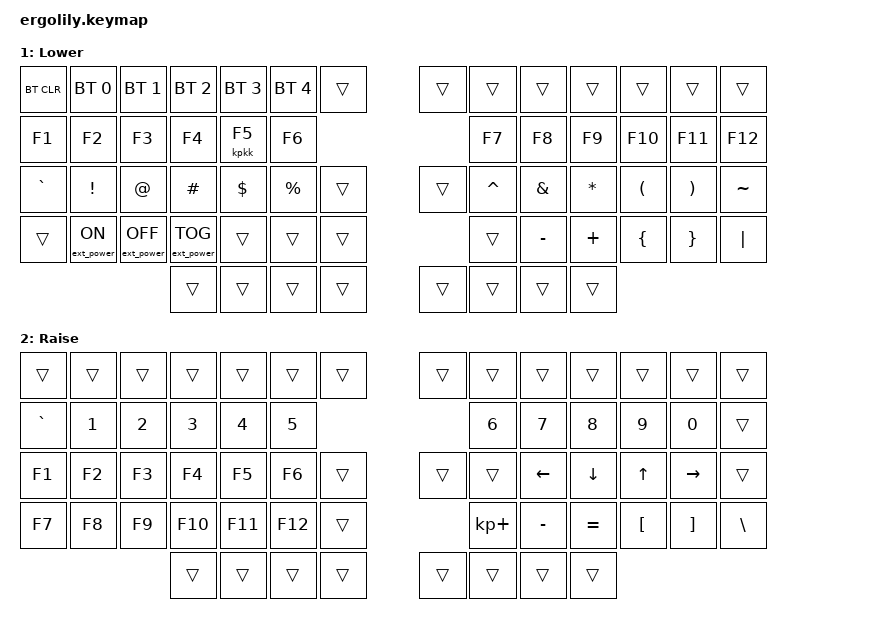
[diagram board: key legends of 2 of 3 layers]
/*
 * Copyright (c) 2020 The ZMK Contributors
 *
 * SPDX-License-Identifier: MIT
 */

 //This file is the board default. It is overridden if there's anything in config/ergolily.conf. I encourage you to edit that instead of this file for a custom keymap, and leave this as the fallback.

#include <behaviors.dtsi>
#include <dt-bindings/zmk/keys.h>
#include <dt-bindings/zmk/bt.h>
#include <dt-bindings/zmk/ext_power.h>

/ {
    keymap {
        compatible = "zmk,keymap";

        default_layer {
            display-name = "Default";
            bindings = <
&kp ESC   &kp N1 &kp N2 &kp N3   &kp N4   &kp N5                                &kp N6    &kp N7   &kp N8       &kp N9      &kp N0      &kp BSPC
&kp TAB   &kp Q  &kp W  &kp E    &kp R    &kp T                                 &kp Y    &kp U     &kp I        &kp O       &kp P       &kp BSLH
&kp LCTRL &kp A  &kp S  &kp D    &kp F    &kp G                                 &kp H    &kp J     &kp K        &kp L       &kp SEMI    &kp SQT
&kp LSHFT &kp Z  &kp X  &kp C    &kp V    &kp B    &kp LBKT        &kp LBKT     &kp N    &kp M     &kp COMMA    &kp DOT     &kp FSLH    &kp RSHFT
                        &kp LALT &kp LGUI &mo 1    &kp SPACE       &kp RET      &mo 2    &kp BSPC  &kp RGUI
            >;
        };

        lower_layer {
            display-name = "Lower";
// ------------------------------------------------------------------------------------------------------------
// | BTCLR | BT1 | BT2 |  BT3 |  BT4 |  BT5 |      |                   |      |      |      |      |      |       |       |
// |  F1   |  F2 |  F3 |  F4  |  F5  |  F6  |      |                   |      |  F7  |  F8  |  F9  | F10  |  F11  |  F12  |
// |   `   |  !  |  @  |  #   |  $   |  %   |      |                   |      |  ^   |  &   |  *   |  (   |   )   |   ~   |
// |       |     |     |      |      |      |      |                   |      |      |  _   |  +   |  {   |   }   |  "|"  |
//                     |      |      |      |      |                   |      |      |      |      |
            bindings = <
&bt BT_CLR &bt BT_SEL 0     &bt BT_SEL 1      &bt BT_SEL 2      &bt BT_SEL 3 &bt BT_SEL 4 &trans                 &trans    &trans    &trans    &trans    &trans    &trans    &trans
&kp F1     &kp F2           &kp F3            &kp F4            &kpkk F5       &kp F6                                          &kp F7    &kp F8    &kp F9    &kp F10   &kp F11   &kp F12
&kp GRAVE  &kp EXCL         &kp AT            &kp HASH          &kp DOLLAR   &kp PRCNT    &trans                 &trans    &kp CARET &kp AMPS  &kp ASTRK &kp LPAR  &kp RPAR  &kp TILDE
&trans     &ext_power EP_ON &ext_power EP_OFF &ext_power EP_TOG &trans       &trans       &trans                           &trans    &kp MINUS &kp PLUS  &kp LBRC  &kp RBRC  &kp PIPE
                                              &trans            &trans       &trans       &trans                 &trans    &trans    &trans    &trans
            >;
        };

        raise_layer {
            display-name = "Raise";
// ------------------------------------------------------------------------------------------------------------
// |       |     |     |      |      |      |      |                   |      |      |      |      |      |       |       |
// |   `   |  1  |  2  |  3   |  4   |  5   |      |                   |      |  6   |  7   |  8   |  9   |   0   |       |
// |  F1   | F2  | F3  |  F4  |  F5  |  F6  |      |                   |      |      | LFT  | DWN  |  UP  |  RGT  |       |
// |  F7   | F8  | F9  |  F10 |  F11 |  F12 |      |                   |      |  +   |  -   |  =   |  [   |   ]   |   \   |
//                     |      |      |      |      |                   |      |      |      |      |
            bindings = <
&trans    &trans &trans &trans  &trans  &trans &trans                       &trans      &trans    &trans    &trans   &trans    &trans    &trans
&kp GRAVE &kp N1 &kp N2 &kp N3  &kp N4  &kp N5                                          &kp N6    &kp N7    &kp N8    &kp N9   &kp N0    &trans
&kp F1    &kp F2 &kp F3 &kp F4  &kp F5  &kp F6 &trans                       &trans     &trans    &kp LEFT  &kp DOWN  &kp UP   &kp RIGHT &trans
&kp F7    &kp F8 &kp F9 &kp F10 &kp F11 &kp F12 &trans                                 &kp KP_PLUS &kp MINUS &kp EQUAL &kp LBKT &kp RBKT  &kp BSLH
                        &trans  &trans  &trans &trans                       &trans     &trans    &trans    &trans
            >;
        };
    };
};
